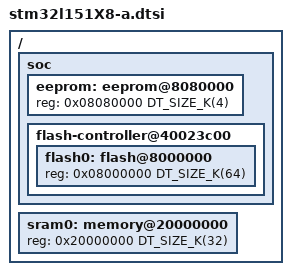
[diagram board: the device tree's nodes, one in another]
/*
 * Copyright (c) 2019 eTactica ehf
 *
 * SPDX-License-Identifier: Apache-2.0
 */

#include <st/l1/stm32l151.dtsi>

/ {
	soc {
		eeprom: eeprom@8080000 {
			reg = <0x08080000 DT_SIZE_K(4)>;
		};

		flash-controller@40023c00 {
			flash0: flash@8000000 {
				reg = <0x08000000 DT_SIZE_K(64)>;
				ranges = <0 0x8000000 DT_SIZE_K(64)>;
			};
		};
	};

	sram0: memory@20000000 {
		reg = <0x20000000 DT_SIZE_K(32)>;
	};
};
